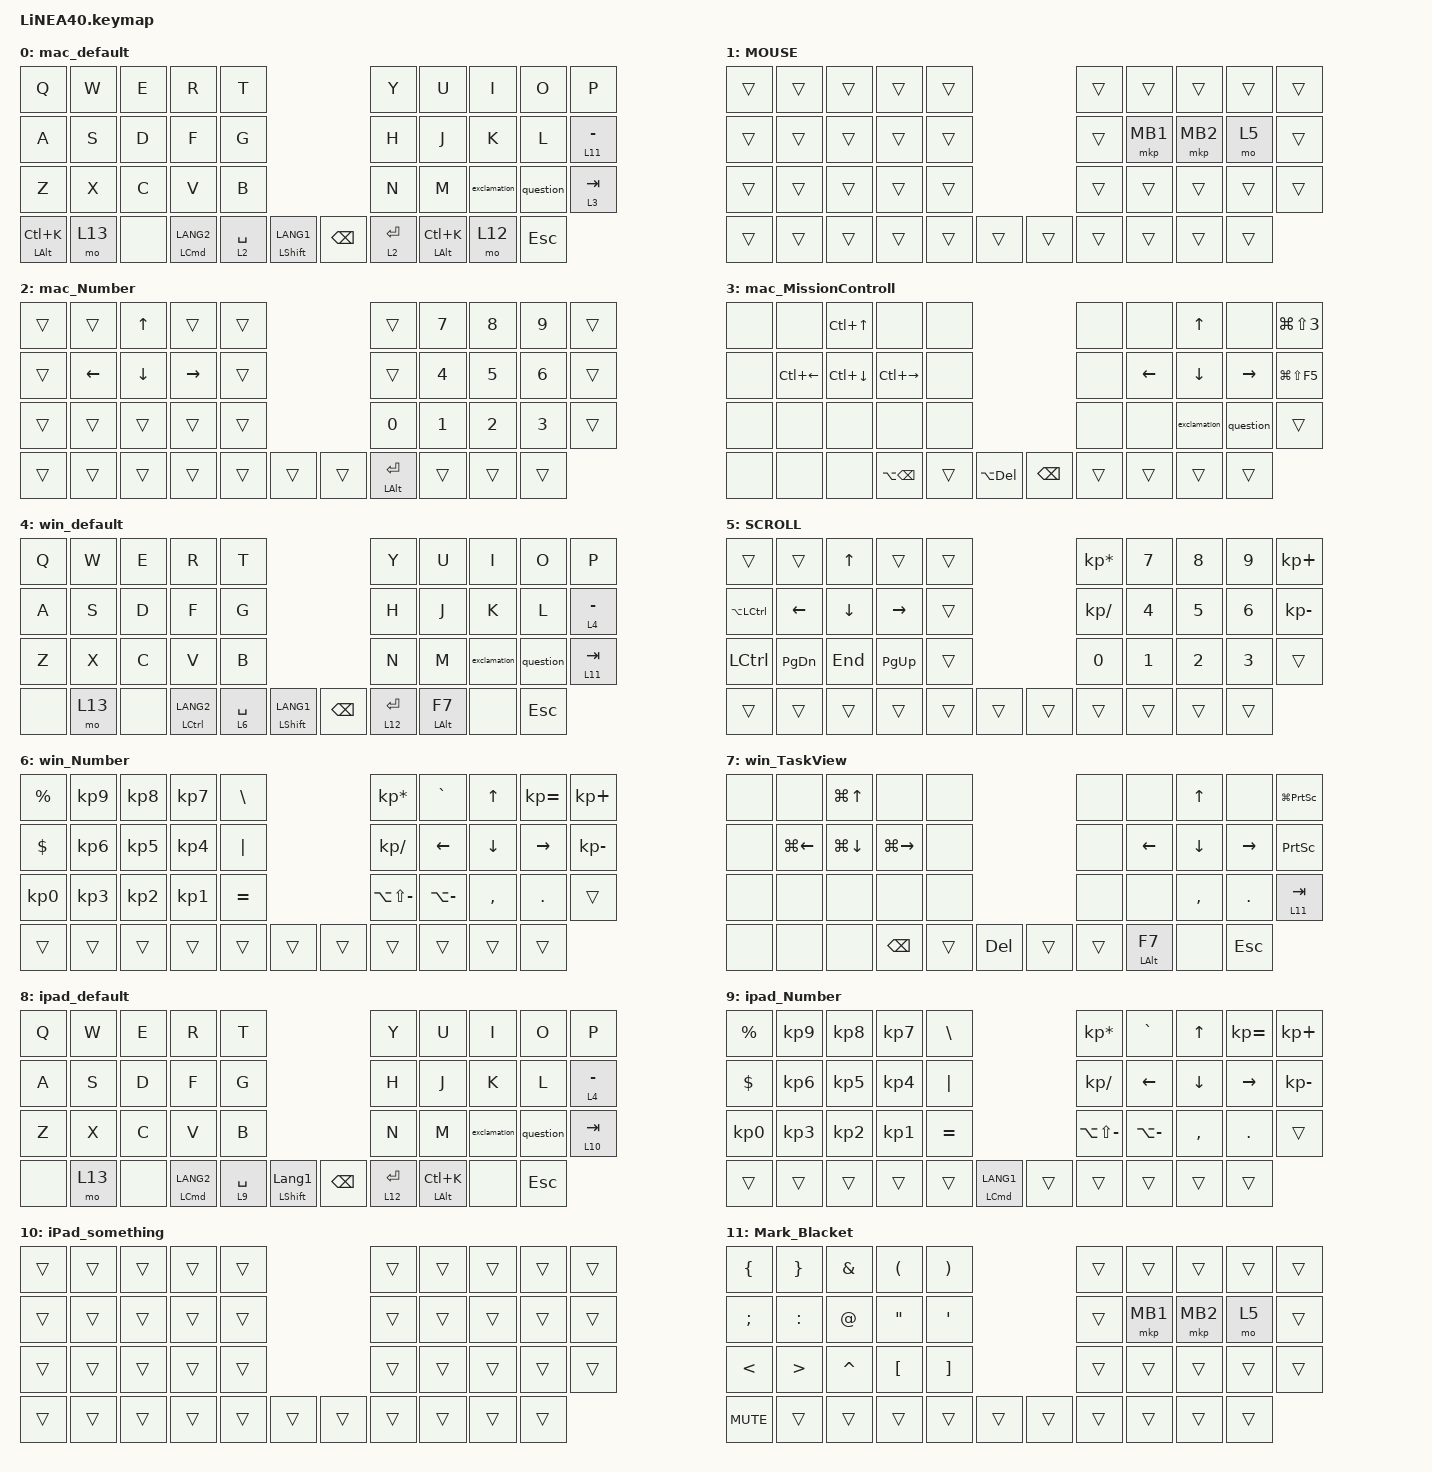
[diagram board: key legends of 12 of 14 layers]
#define ZMK_POINTING_DEFAULT_SCRL_VAL 150

#include <dt-bindings/zmk/input_transform.h>
#include <input/processors.dtsi>
#include <zephyr/dt-bindings/input/input-event-codes.h>
#include <behaviors.dtsi>
#include <dt-bindings/zmk/bt.h>
#include <dt-bindings/zmk/keys.h>
#include <dt-bindings/zmk/pointing.h>

#define MOUSE 1
#define MARK 2
#define CURSOR 3
#define FUNCTION 4
#define SCROLL 5
#define WIRELESS 6

//mouse cursol

&mmv {
    delay-ms = <20>;
    trigger-period-ms = <5>;
    time-to-max-speed-ms = <100>;
    acceleration-exponent = <2>;
};

//mouse scroll

&msc {
    delay-ms = <3>;
    trigger-period-ms = <3>;
    time-to-max-speed-ms = <100>;
    acceleration-exponent = <0>;
};

/ {
    input_processors {
        zip_wheel_scaler: zip_wheel_scaler {
            compatible = "zmk,input-processor-scaler";
            #input-processor-cells = <2>;
            type = <INPUT_EV_REL>;
            codes = <INPUT_REL_WHEEL>;
            track-remainders;
        };
    };
};

&msc_input_listener {
    speed_up {
        layers = <FUNCTION>;
        input-processors = <&zip_wheel_scaler 3 1>; //スクロールを3倍速にする
    };
};

&trackball_listener {
    scroller {
        layers = <SCROLL>;
        input-processors =
            <&zip_xy_transform INPUT_TRANSFORM_Y_INVERT>,
            //スクロール方向を逆転,,,,,,,,,,,,,,,,,,,,,,,,,,,,,,,,,,,,,,,,,,,,,,,,,,,,,,,
            <&zip_xy_to_scroll_mapper>;
    };
};

/ {
    combos {
        compatible = "zmk,combos";

        ZenkakuHankaku {
            bindings = <&kp GRAVE>;
            key-positions = <11 12>;
        };

        DeleteKey {
            bindings = <&kp DEL>;
            key-positions = <7 8>;
        };

        InsertKey {
            bindings = <&kp INS>;
            key-positions = <6 7>;
        };

        CenterClick {
            bindings = <&mkp MB3>;
            key-positions = <16 17>;
        };

        RightClick {
            bindings = <&mkp MB2>;
            key-positions = <18 17>;
        };

        PrevClick {
            bindings = <&mkp MB4>;
            key-positions = <27 28>;
        };

        ClickNext {
            bindings = <&mkp MB5>;
            key-positions = <26 27>;
        };
    };

    behaviors {
        re_kp: sensor_rotate_kp {
            compatible = "zmk,behavior-sensor-rotate-var";
            #sensor-binding-cells = <2>;
            bindings = <&kp>, <&kp>;
        };

        mouse_scrl: mouse_wheel_scrl {
            compatible = "zmk,behavior-sensor-rotate-var";
            #sensor-binding-cells = <2>;
            bindings = <&msc>, <&msc>;

            tap-ms = <20>;
        };

        exclamation: exclamation {
            compatible = "zmk,behavior-mod-morph";
            label = "EXCLAMATION";
            bindings = <&kp COMMA>, <&kp NUMBER_1>;

            #binding-cells = <0>;
            mods = <(MOD_LSFT)>;
            keep-mods = <(MOD_LSFT)>;
        };

        question: question {
            compatible = "zmk,behavior-mod-morph";
            label = "QUESTION";
            bindings = <&kp PERIOD>, <&kp SLASH>;

            #binding-cells = <0>;
            mods = <(MOD_LSFT)>;
            keep-mods = <(MOD_LSFT)>;
        };
    };

    macros {
        bt1_mac: bt1_mac {
            compatible = "zmk,behavior-macro";
            #binding-cells = <0>;
            bindings = <&bt BT_SEL 0>, <&macro_tap_time 200>, <&to 0>;

            label = "BT1_MAC";
        };

        bt2_LabWin: bt2_LabWin {
            compatible = "zmk,behavior-macro";
            #binding-cells = <0>;
            bindings = <&bt BT_SEL 2>, <&macro_wait_time 200>, <&to 4>;

            label = "BT2_LABWIN";
        };

        bt3_HomeWin: bt3_HomeWin {
            compatible = "zmk,behavior-macro";
            #binding-cells = <0>;
            bindings = <&bt BT_SEL 3>, <&macro_wait_time 200>, <&to 4>;

            label = "BT3_HOMEWIN";
        };
    };

    keymap {
        compatible = "zmk,keymap";

        mac_default {
            bindings = <
&kp Q               &kp W   &kp E  &kp R                   &kp T                                               &kp Y        &kp U  &kp I               &kp O      &kp P
&kp A               &kp S   &kp D  &kp F                   &kp G                                               &kp H        &kp J  &kp K               &kp L      &lt 11 MINUS
&kp Z               &kp X   &kp C  &kp V                   &kp B                                               &kp N        &kp M  &exclamation        &question  &lt 3 TAB
&mt LEFT_ALT LC(K)  &mo 13  &none  &mt LEFT_COMMAND LANG2  &lt 2 SPACE  &mt LEFT_SHIFT LANG1    &kp BACKSPACE  &lt 2 ENTER         &mt LEFT_ALT LC(K)  &mo 12     &kp ESCAPE
            >;

            sensor-bindings = <&mouse_scrl SCRL_DOWN SCRL_UP>;
        };

        MOUSE {
            bindings = <
&trans  &trans  &trans  &trans  &trans                    &trans  &trans    &trans    &trans  &trans
&trans  &trans  &trans  &trans  &trans                    &trans  &mkp MB1  &mkp MB2  &mo 5   &trans
&trans  &trans  &trans  &trans  &trans                    &trans  &trans    &trans    &trans  &trans
&trans  &trans  &trans  &trans  &trans  &trans    &trans  &trans            &trans    &trans  &trans
            >;
        };

        mac_Number {
            bindings = <
&trans  &trans          &kp UP_ARROW    &trans           &trans                    &trans              &kp N7  &kp N8  &kp N9  &trans
&trans  &kp LEFT_ARROW  &kp DOWN_ARROW  &kp RIGHT_ARROW  &trans                    &trans              &kp N4  &kp N5  &kp N6  &trans
&trans  &trans          &trans          &trans           &trans                    &kp N0              &kp N1  &kp N2  &kp N3  &trans
&trans  &trans          &trans          &trans           &trans  &trans    &trans  &mt LEFT_ALT ENTER          &trans  &trans  &trans
            >;

            sensor-bindings = <&mouse_scrl SCRL_DOWN SCRL_UP>;
        };

        mac_MissionControll {
            bindings = <
&none  &none               &kp LC(UP_ARROW)  &none                &none                                    &none   &none     &kp UP_ARROW  &none            &kp LG(LS(NUMBER_3))
&none  &kp LC(LEFT_ARROW)  &kp LC(DOWN)      &kp LC(RIGHT_ARROW)  &none                                    &none   &kp LEFT  &kp DOWN      &kp RIGHT_ARROW  &kp LG(LS(F5))
&none  &none               &none             &none                &none                                    &none   &none     &exclamation  &question        &trans
&none  &none               &none             &kp LA(BACKSPACE)    &trans  &kp LA(DELETE)    &kp BACKSPACE  &trans            &trans        &trans           &trans
            >;

            sensor-bindings = <&re_kp LG(EQUAL) LG(MINUS)>;
        };

        win_default {
            bindings = <
&kp Q  &kp W   &kp E  &kp R            &kp T                                               &kp Y         &kp U  &kp I            &kp O      &kp P
&kp A  &kp S   &kp D  &kp F            &kp G                                               &kp H         &kp J  &kp K            &kp L      &lt 4 MINUS
&kp Z  &kp X   &kp C  &kp V            &kp B                                               &kp N         &kp M  &exclamation     &question  &lt 11 TAB
&none  &mo 13  &none  &mt LCTRL LANG2  &lt 6 SPACE  &mt LEFT_SHIFT LANG1    &kp BACKSPACE  &lt 12 ENTER         &mt LEFT_ALT F7  &none      &kp ESCAPE
            >;

            sensor-bindings = <&mouse_scrl SCRL_DOWN SCRL_UP>;
        };

        SCROLL {
            bindings = <
&trans         &trans          &kp UP_ARROW  &trans           &trans                    &kp KP_MULTIPLY  &kp NUMBER_7  &kp NUMBER_8  &kp NUMBER_9  &kp KP_PLUS
&kp LA(LCTRL)  &kp LEFT_ARROW  &kp DOWN      &kp RIGHT_ARROW  &trans                    &kp KP_SLASH     &kp NUMBER_4  &kp NUMBER_5  &kp NUMBER_6  &kp KP_MINUS
&kp LCTRL      &kp PAGE_DOWN   &kp END       &kp PAGE_UP      &trans                    &kp N0           &kp NUMBER_1  &kp NUMBER_2  &kp NUMBER_3  &trans
&trans         &trans          &trans        &trans           &trans  &trans    &trans  &trans                         &trans        &trans        &trans
            >;

            sensor-bindings = <&re_kp LG(EQUAL) LG(MINUS)>;
        };

        win_Number {
            bindings = <
&kp PERCENT      &kp KP_NUMBER_9  &kp KP_NUMBER_8  &kp KP_NUMBER_7  &kp BACKSLASH                    &kp KP_ASTERISK    &kp GRAVE      &kp UP_ARROW  &kp KP_EQUAL  &kp KP_PLUS
&kp DOLLAR       &kp KP_NUMBER_6  &kp KP_NUMBER_5  &kp KP_NUMBER_4  &kp PIPE                         &kp KP_SLASH       &kp LEFT       &kp DOWN      &kp RIGHT     &kp KP_MINUS
&kp KP_NUMBER_0  &kp KP_NUMBER_3  &kp KP_NUMBER_2  &kp KP_NUMBER_1  &kp EQUAL                        &kp LA(LS(MINUS))  &kp LA(MINUS)  &kp COMMA     &kp PERIOD    &trans
&trans           &trans           &trans           &trans           &trans         &trans    &trans  &trans                            &trans        &trans        &trans
            >;

            sensor-bindings = <&mouse_scrl SCRL_DOWN SCRL_UP>;
        };

        win_TaskView {
            bindings = <
&none  &none               &kp LG(UP_ARROW)  &none                &none                         &none   &none     &kp UP_ARROW     &none            &kp LG(PRINTSCREEN)
&none  &kp LG(LEFT_ARROW)  &kp LG(DOWN)      &kp LG(RIGHT_ARROW)  &none                         &none   &kp LEFT  &kp DOWN         &kp RIGHT_ARROW  &kp PRINTSCREEN
&none  &none               &none             &none                &none                         &none   &none     &kp COMMA        &kp PERIOD       &lt 11 TAB
&none  &none               &none             &kp BACKSPACE        &trans  &kp DELETE    &trans  &trans            &mt LEFT_ALT F7  &none            &kp ESC
            >;

            sensor-bindings = <&re_kp LG(EQUAL) LG(MINUS)>;
        };

        ipad_default {
            bindings = <
&kp Q  &kp W   &kp E  &kp R                   &kp T                                                    &kp Y         &kp U  &kp I               &kp O      &kp P
&kp A  &kp S   &kp D  &kp F                   &kp G                                                    &kp H         &kp J  &kp K               &kp L      &lt 4 MINUS
&kp Z  &kp X   &kp C  &kp V                   &kp B                                                    &kp N         &kp M  &exclamation        &question  &lt 10 TAB
&none  &mo 13  &none  &mt LEFT_COMMAND LANG2  &lt 9 SPACE  &mt LEFT_SHIFT LANGUAGE_1    &kp BACKSPACE  &lt 12 ENTER         &mt LEFT_ALT LC(K)  &none      &kp ESCAPE
            >;

            sensor-bindings = <&mouse_scrl SCRL_DOWN SCRL_UP>;
        };

        ipad_Number {
            bindings = <
&kp PERCENT      &kp KP_NUMBER_9  &kp KP_NUMBER_8  &kp KP_NUMBER_7  &kp BACKSLASH                                    &kp KP_ASTERISK    &kp GRAVE      &kp UP_ARROW  &kp KP_EQUAL  &kp KP_PLUS
&kp DOLLAR       &kp KP_NUMBER_6  &kp KP_NUMBER_5  &kp KP_NUMBER_4  &kp PIPE                                         &kp KP_SLASH       &kp LEFT       &kp DOWN      &kp RIGHT     &kp KP_MINUS
&kp KP_NUMBER_0  &kp KP_NUMBER_3  &kp KP_NUMBER_2  &kp KP_NUMBER_1  &kp EQUAL                                        &kp LA(LS(MINUS))  &kp LA(MINUS)  &kp COMMA     &kp PERIOD    &trans
&trans           &trans           &trans           &trans           &trans         &mt LEFT_COMMAND LANG1    &trans  &trans                            &trans        &trans        &trans
            >;

            sensor-bindings = <&mouse_scrl SCRL_DOWN SCRL_UP>;
        };

        iPad_something {
            bindings = <
&trans  &trans  &trans  &trans  &trans                    &trans  &trans  &trans  &trans  &trans
&trans  &trans  &trans  &trans  &trans                    &trans  &trans  &trans  &trans  &trans
&trans  &trans  &trans  &trans  &trans                    &trans  &trans  &trans  &trans  &trans
&trans  &trans  &trans  &trans  &trans  &trans    &trans  &trans          &trans  &trans  &trans
            >;
        };

        Mark_Blacket {
            bindings = <
&kp LEFT_BRACE  &kp RIGHT_BRACE   &kp AMPERSAND  &kp LEFT_PARENTHESIS  &kp RIGHT_PARENTHESIS                    &trans  &trans    &trans    &trans  &trans
&kp SEMICOLON   &kp COLON         &kp AT         &kp DOUBLE_QUOTES     &kp SQT                                  &trans  &mkp MB1  &mkp MB2  &mo 5   &trans
&kp LESS_THAN   &kp GREATER_THAN  &kp CARET      &kp LEFT_BRACKET      &kp RIGHT_BRACKET                        &trans  &trans    &trans    &trans  &trans
&kp K_MUTE      &trans            &trans         &trans                &trans                 &trans    &trans  &trans            &trans    &trans  &trans
            >;

            sensor-bindings = <&re_kp C_VOLUME_UP C_VOLUME_DOWN>;
        };

        Function_Windowmanagement {
            bindings = <
&none   &none   &none   &none   &none                     &none   &kp F1  &kp F2   &kp F3   &kp F4
&none   &none   &none   &none   &none                     &none   &kp F5  &kp F6   &kp F7   &kp F8
&none   &none   &none   &none   &none                     &none   &kp F9  &kp F10  &kp F11  &kp F12
&trans  &trans  &trans  &trans  &trans  &trans    &trans  &trans          &trans   &trans   &trans
            >;
        };

        Bluetooth {
            bindings = <
&bt1_mac  &bt2_LabWin  &bt3_HomeWin  &none   &trans                    &bt BT_CLR_ALL  &trans  &trans  &trans  &trans
&trans    &trans       &trans        &trans  &trans                    &trans          &trans  &trans  &trans  &trans
&trans    &trans       &trans        &trans  &trans                    &trans          &trans  &trans  &trans  &trans
&trans    &trans       &trans        &trans  &trans  &trans    &trans  &trans                  &trans  &trans  &trans
            >;
        };
    };
};
